# eh2 register map
Vendor: Syntronix Corp.; Series: Core-VeeR; File version: 1.4
32-bit RISC-V Microcontroller based device, CPU clock up to 50MHz, etc.
CPU: other r1p0, little endian, MPU, no FPU, 3 interrupt priority bits
Registers are 8-bit, read-write, reset 0x0 unless marked. A register's access mark holds for its fields unless they carry their own. Offsets are from the block's base; lines under a group give offsets from that group; [hi:lo] are bit positions; {n}, {i} and the like mark numbered series; 'fields as' and 'values as' point back to an identical list; <NAME> marks a mode.

## Memory map
0x80001000 SYSCON size 0x40 — System Controller Peripheral for VeeRwolf SoC
0x80001040 SPI size 0x10 — Serial Peripheral Interface (SPI) with Union/Aliasing Registers
0x80002000 UART size 0x10 — UART16550 IP Core with Wishbone Interface

## Interrupts
1 UART — UART Interrupt Output Signal
2 SPI — SPI Interrupt Output Signal

## SYSCON — System Controller Peripheral for VeeRwolf SoC
Base 0x80001000
0x00 VERSION_PATCH ro — VeeRwolf patch version
  [7:0] PATCH — Patch version number
0x01 VERSION_MINOR ro — VeeRwolf minor version
  [7:0] MINOR — Minor version number
0x02 VERSION_MAJOR ro — VeeRwolf major version
  [7:0] MAJOR — Major version number
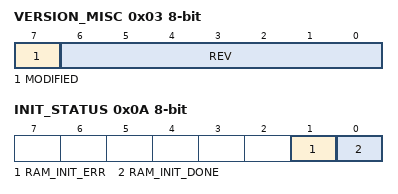
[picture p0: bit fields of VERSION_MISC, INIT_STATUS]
0x03 VERSION_MISC ro — VeeRwolf misc version info
  [7] MODIFIED — Set when VeeRwolf was built from modified sources
  [6:0] REV — Revision since last patch version
0x04 VERSION_SHA 32-bit ro — SHA hash of the build
  [31:0] SHA — Build SHA hash
0x08 SIM_PRINT wo — Outputs a character in simulation. No effect on hardware
  [7:0] CHAR — Character output to simulation console
0x09 SIM_EXIT wo — Exits a simulation. No effect on hardware
  [7:0] EXIT_CODE — Simulation exit code
0x0A INIT_STATUS ro — RAM Initialization Status
  [1] RAM_INIT_ERR — RAM initialization reported errors
  [0] RAM_INIT_DONE — RAM initialization complete
0x0B SW_IRQ — Software-controlled external interrupts
  [7:0] SW_IRQ — Software interrupt bits
0x0C NMI_VEC 32-bit — Interrupt vector for NMI
  [31:0] VEC — NMI vector address
0x10 GPIO0 32-bit — 32 readable and writable GPIO bits
  [31:0] PINS — GPIO0 pins state/control
0x18 GPIO1 32-bit — 32 readable and writable GPIO bits
  [31:0] PINS — GPIO1 pins state/control
0x20 MTIMEL 32-bit — mtime from RISC-V privilege spec
0x24 MTIMEH 32-bit — mtime from RISC-V privilege spec
0x28 MTIMECMPL 32-bit — mtimecmp from RISC-V privilege spec
0x2C MTIMECMPH 32-bit — mtimecmp from RISC-V privilege spec
0x30 IRQ_TIMER_CNT 32-bit — IRQ timer counter
  [31:0] CNT — IRQ timer count value
0x34 IRQ_TIMER_CTRL — IRQ timer control
  [7:0] CTRL — IRQ timer control flags
0x3C CLK_FREQ_HZ 32-bit ro — Clock frequency of main clock in Hz

## SPI — Serial Peripheral Interface (SPI) with Union/Aliasing Registers
Base 0x80001040
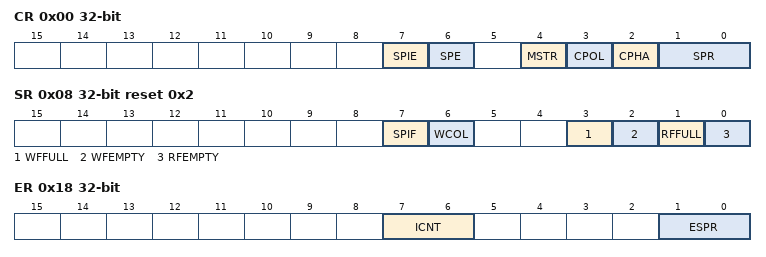
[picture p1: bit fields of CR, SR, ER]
0x00 CR 32-bit — Simple SPI Control register
  [7] SPIE — Serial Peripheral Interrupt Enable
  [6] SPE — Serial Peripheral Enable
  [4] MSTR — Master Mode Select
  [3] CPOL — Clock Polarity
  [2] CPHA — Clock Phase
  [1:0] SPR — SPI Clock Rate Select
0x08 SR 32-bit reset 0x2 — Simple SPI status register
  [7] SPIF — Serial Peripheral Interrupt Flag
  [6] WCOL — Write Collision Flag
  [3] WFFULL — Write FIFO Full
  [2] WFEMPTY — Write FIFO Empty
  [1] RFFULL — Read FIFO Full
  [0] RFEMPTY — Read FIFO Empty
0x10 DR 32-bit — Simple SPI data register
0x18 ER 32-bit — Simple SPI extended register
  [7:6] ICNT — Interrupt Count. 00 SPIF is set after every completed transfer. 01 SPIF is set after every two completed transfers. 10 SPIF is set after every three completed transfers. 11 SPIF is set after every four completed transfers
  [1:0] ESPR — Extended SPI Clock Rate Select. 00 SPR is used to generate the SPI clock. 01 SPR is multiplied by 2 to generate the SPI clock. 10 SPR is multiplied by 4 to generate the SPI clock. 11 SPR is multiplied by 8 to generate the SPI clock
0x20 SS 32-bit — Simple SPI slave select register

## UART — UART16550 IP Core with Wishbone Interface
Base 0x80002000
0x00 RBR ro — Receiver Buffer Register (Read Only, DLAB=0)
  [7:0] RBR — Receiver FIFO output byte
0x00 THR wo (alternate view of RBR) — Transmitter Holding Register (Write Only, DLAB=0)
  [7:0] THR — Transmit FIFO input byte
0x00 DLL (alternate view of RBR) — Divisor Latch Byte 1 LSB (Read/Write, DLAB=1)
  [7:0] DLL — The LSB of the divisor latch
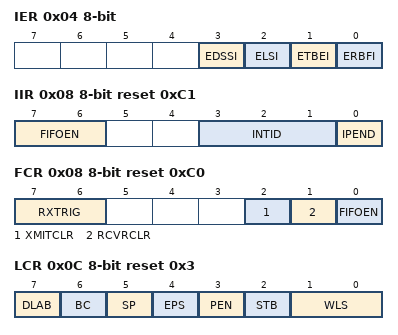
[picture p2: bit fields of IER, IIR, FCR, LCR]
0x04 IER — Interrupt Enable Register (Read/Write, DLAB=0)
  [3] EDSSI — Enable Modem Status Interrupt
  [2] ELSI — Enable Receiver Line Status Interrupt
  [1] ETBEI — Enable Transmitter Holding Register Empty Interrupt
  [0] ERBFI — Enable Received Data Available Interrupt
0x04 DLM (alternate view of IER) — Divisor Latch Byte 2 MSB (Read/Write, DLAB=1)
  [7:0] DLM — The MSB of the divisor latch
0x08 IIR ro reset 0xC1 — Interrupt Identification Register (Read Only)
  [7:6] FIFOEN — FIFOs Enabled indicator (Fixed logic '11')
  [3:1] INTID — Interrupt Identification ID
  [0] IPEND — Interrupt Pending ('0': Pending, '1': No interrupt pending)
0x08 FCR wo reset 0xC0 (alternate view of IIR) — FIFO Control Register (Write Only)
  [7:6] RXTRIG — Receiver FIFO Interrupt Trigger Level ('00':1B, '01':4B, '10':8B, '11':14B)
  [2] XMITCLR — Transmitter FIFO Clear
  [1] RCVRCLR — Receiver FIFO Clear
  [0] FIFOEN — FIFO Enable (Ignored in core)
0x0C LCR reset 0x3 — Line Control Register (Read/Write)
  [7] DLAB — Divisor Latch Access Bit
  [6] BC — Break Control
  [5] SP — Stick Parity
  [4] EPS — Even Parity Select
  [3] PEN — Parity Enable
  [2] STB — Stop Bit Select
  [1:0] WLS — Word Length Select ('00':5b, '01':6b, '10':7b, '11':8b)
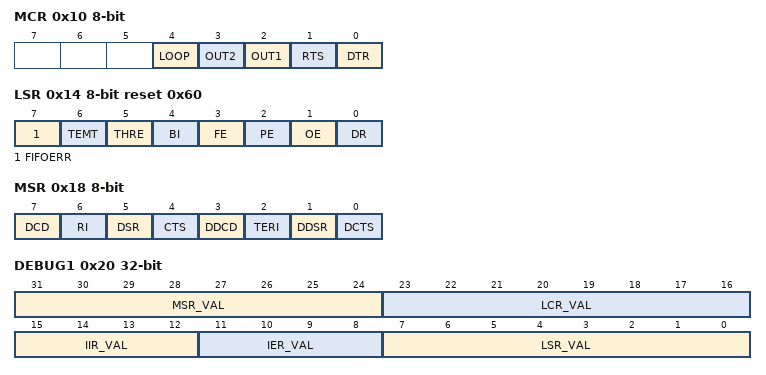
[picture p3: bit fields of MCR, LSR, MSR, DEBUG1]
0x10 MCR wo — Modem Control Register (Write Only)
  [4] LOOP — Loopback Mode Select
  [3] OUT2 — Out2 Output Control
  [2] OUT1 — Out1 Output Control
  [1] RTS — Request To Send Control
  [0] DTR — Data Terminal Ready Control
0x14 LSR ro reset 0x60 — Line Status Register (Read Only)
  [7] FIFOERR — Error in Receiver FIFO Indicator
  [6] TEMT — Transmitter Empty Indicator
  [5] THRE — Transmitter Holding Register Empty Indicator
  [4] BI — Break Interrupt Indicator
  [3] FE — Framing Error Indicator
  [2] PE — Parity Error Indicator
  [1] OE — Overrun Error Indicator
  [0] DR — Data Ready Indicator
0x18 MSR ro — Modem Status Register (Read Only)
  [7] DCD — Complement of DCD input (or Out2 in Loopback)
  [6] RI — Complement of RI input (or Out1 in Loopback)
  [5] DSR — Complement of DSR input (or DTR in Loopback)
  [4] CTS — Complement of CTS input (or RTS in Loopback)
  [3] DDCD — Delta Data Carrier Detect Indicator
  [2] TERI — Trailing Edge Ring Indicator Detector
  [1] DDSR — Delta Data Set Ready Indicator
  [0] DCTS — Delta Clear To Send Indicator
0x20 DEBUG1 32-bit ro — Debug Register 1 (Read Only, 32-bit mode)
  [31:24] MSR_VAL — Modem Status Register value
  [23:16] LCR_VAL — Line Control Register value
  [15:12] IIR_VAL — Interrupt Identifier Register value (bits 3-0)
  [11:8] IER_VAL — Interrupt Enable Register value (bits 3-0)
  [7:0] LSR_VAL — Line Status Register value
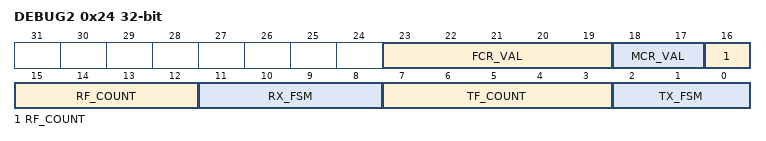
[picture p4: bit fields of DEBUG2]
0x24 DEBUG2 32-bit ro — Debug Register 2 (Read Only, 32-bit mode)
  [23:19] FCR_VAL — FIFO Control Register value (bits 7-6)
  [18:17] MCR_VAL — Modem Control Register value (bits 4-0)
  [16:12] RF_COUNT — Number of characters in Receiver FIFO
  [11:8] RX_FSM — Receiver FSM state
  [7:3] TF_COUNT — Number of characters in Transmitter FIFO
  [2:0] TX_FSM — Transmitter FSM state

## Licence text in the file
Copyright (c) 2014-2026 Syntronix AI Corp. All rights reserved. Software License Agreement . THIS SOFTWARE IS PROVIDED "AS IS" AND WITH ALL FAULTS. NO WARRANTIES, WHETHER EXPRESS, IMPLIED OR STATUTORY, INCLUDING, BUT. NOT LIMITED TO, IMPLIED WARRANTIES OF MERCHANTABILITY AND FITNESS FOR. A PARTICULAR PURPOSE APPLY TO THIS SOFTWARE. TI SHALL NOT, UNDER ANY. CIRCUMSTANCES, BE LIABLE FOR SPECIAL, INCIDENTAL, OR CONSEQUENTIAL. DAMAGES, FOR ANY REASON WHATSOEVER.

## Notices in the file
Copyright (C) 2012 ARM Limited. All rights reserved.
Purpose: System Viewer Description (SVD) Example (Schema Version 1.1)
This is a description of a none-existent and incomplete device
for demonstration purposes only.
Redistribution and use in source and binary forms, with or without
modification, are permitted provided that the following conditions are met:
- Redistributions of source code must retain the above copyright
notice, this list of conditions and the following disclaimer.
- Redistributions in binary form must reproduce the above copyright
notice, this list of conditions and the following disclaimer in the
documentation and/or other materials provided with the distribution.
- Neither the name of ARM nor the names of its contributors may be used
to endorse or promote products derived from this software without
specific prior written permission.
THIS SOFTWARE IS PROVIDED BY THE COPYRIGHT HOLDERS AND CONTRIBUTORS "AS IS"
AND ANY EXPRESS OR IMPLIED WARRANTIES, INCLUDING, BUT NOT LIMITED TO, THE
ARE DISCLAIMED. IN NO EVENT SHALL COPYRIGHT HOLDERS AND CONTRIBUTORS BE
LIABLE FOR ANY DIRECT, INDIRECT, INCIDENTAL, SPECIAL, EXEMPLARY, OR
CONSEQUENTIAL DAMAGES (INCLUDING, BUT NOT LIMITED TO, PROCUREMENT OF
SUBSTITUTE GOODS OR SERVICES; LOSS OF USE, DATA, OR PROFITS; OR BUSINESS
INTERRUPTION) HOWEVER CAUSED AND ON ANY THEORY OF LIABILITY, WHETHER IN
CONTRACT, STRICT LIABILITY, OR TORT (INCLUDING NEGLIGENCE OR OTHERWISE)
ARISING IN ANY WAY OUT OF THE USE OF THIS SOFTWARE, EVEN IF ADVISED OF THE
POSSIBILITY OF SUCH DAMAGE.
